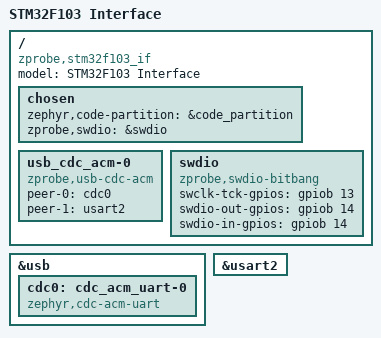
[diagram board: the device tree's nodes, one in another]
/*
 * Copyright (c) 2023 XiNGRZ
 * SPDX-License-Identifier: Apache-2.0
 */

/dts-v1/;
#include "common.dtsi"

/ {
	model = "STM32F103 Interface";
	compatible = "zprobe,stm32f103_if", "st,stm32f103";

	chosen {
		zephyr,code-partition = &code_partition;
		zprobe,swdio = &swdio;
	};
};

&usb {
	cdc0: cdc_acm_uart-0 {
		compatible = "zephyr,cdc-acm-uart";
	};
};

&usart2 {
	status = "okay";
};

/ {
	usb_cdc_acm-0 {
		compatible = "zprobe,usb-cdc-acm";
		peer-0 = <&cdc0>;
		peer-1 = <&usart2>;
	};
};

/ {
	swdio: swdio {
		compatible = "zprobe,swdio-bitbang";
		swclk-tck-gpios = <&gpiob 13 GPIO_PULL_UP>;
		swdio-out-gpios = <&gpiob 14 GPIO_PULL_UP>;
		swdio-in-gpios = <&gpiob 14 GPIO_PULL_UP>;
	};
};
